VERSION "Cummins_J1939_Proprietary_v1.0"

NS_ :

BS_:

BU_: ECM_Cummins

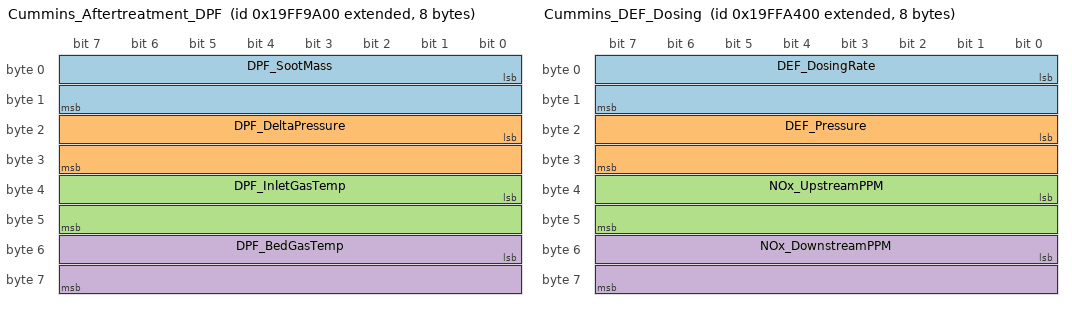
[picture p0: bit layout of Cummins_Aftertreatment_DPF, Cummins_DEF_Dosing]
BO_ 2583665152 Cummins_Aftertreatment_DPF: 8 ECM_Cummins
 SG_ DPF_SootMass : 0|16@1+ (0.1,0) [0|6553.5] "g" Vector__XXX
 SG_ DPF_DeltaPressure : 16|16@1+ (0.1,0) [0|6553.5] "kPa" Vector__XXX
 SG_ DPF_InletGasTemp : 32|16@1+ (0.03125,-273) [-273|1774] "degC" Vector__XXX
 SG_ DPF_BedGasTemp : 48|16@1+ (0.03125,-273) [-273|1774] "degC" Vector__XXX

BO_ 2583667712 Cummins_DEF_Dosing: 8 ECM_Cummins
 SG_ DEF_DosingRate : 0|16@1+ (0.1,0) [0|6553.5] "mL/h" Vector__XXX
 SG_ DEF_Pressure : 16|16@1+ (1,0) [0|65535] "kPa" Vector__XXX
 SG_ NOx_UpstreamPPM : 32|16@1+ (0.05,-200) [-200|3076] "ppm" Vector__XXX
 SG_ NOx_DownstreamPPM : 48|16@1+ (0.05,-200) [-200|3076] "ppm" Vector__XXX

CM_ "Cummins ISX / X15 / B6.7 Engine CM2350 / CM2450 Proprietary J1939 DBC";
